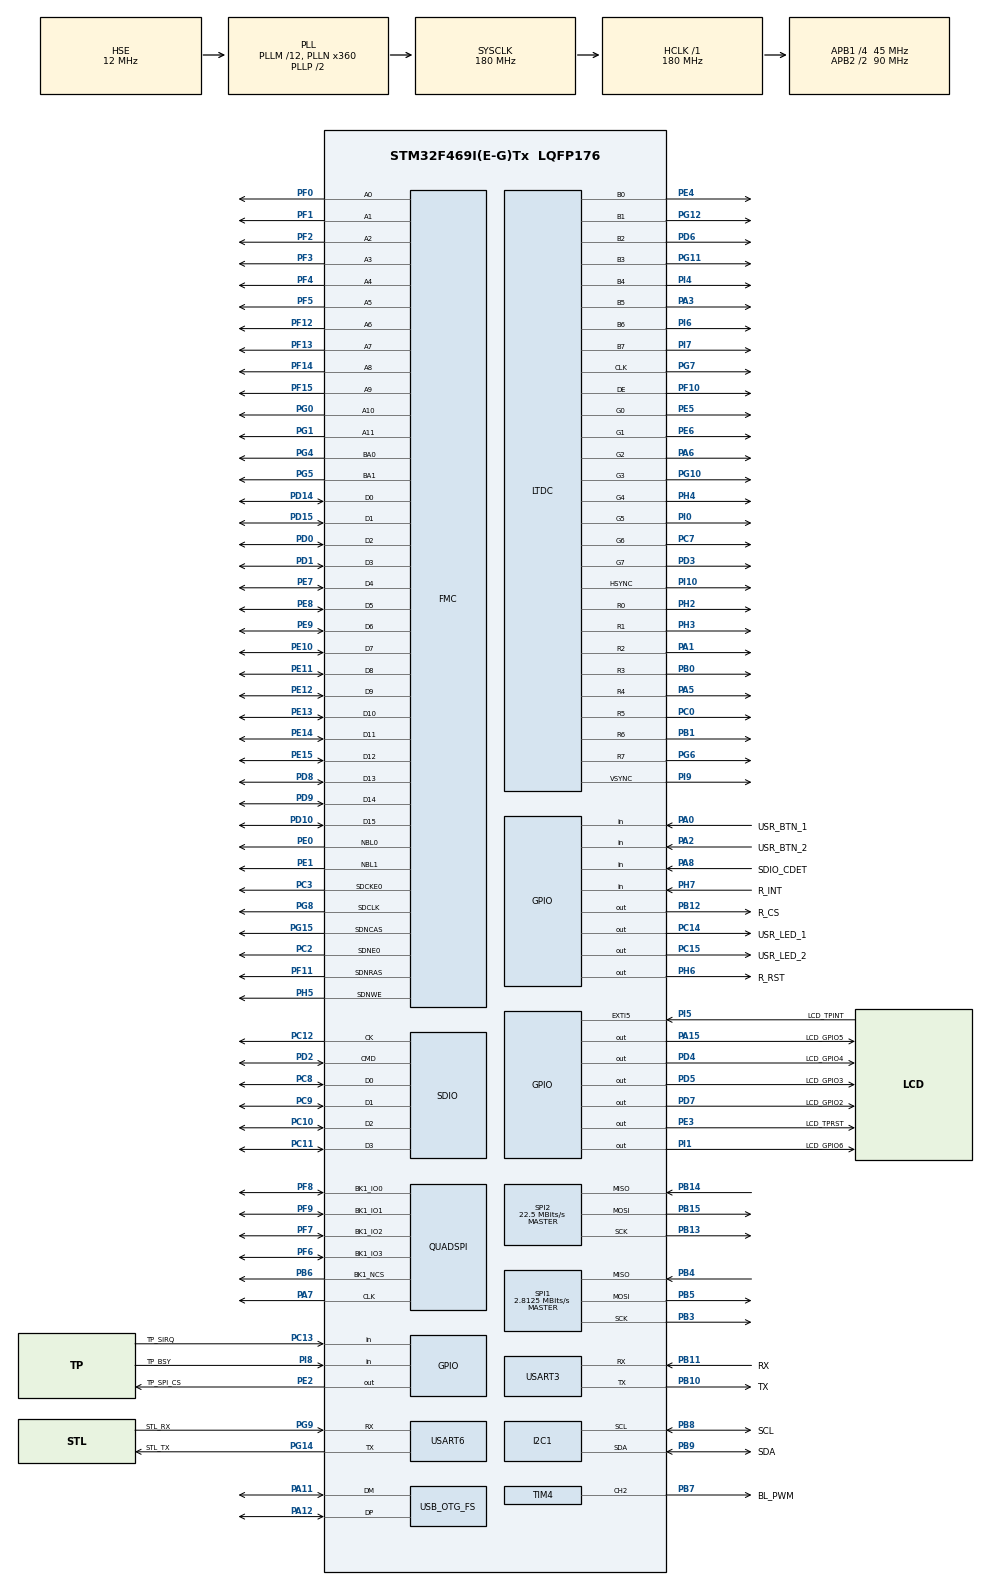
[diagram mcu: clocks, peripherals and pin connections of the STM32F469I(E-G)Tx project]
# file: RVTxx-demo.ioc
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SH.FMC_D7_DA7.0=FMC_D7,sd-16b-d1
VP_SYS_VS_tim6.Mode=TIM6
FMC.RCDDelay1=2
FMC.SDClockPeriod1=FMC_SDRAM_CLOCK_PERIOD_2
SH.FMC_A0.0=FMC_A0,12b-sda1
QUADSPI.ClockPrescaler=1
SPI1.VirtualType=VM_MASTER
FATFS0.BSP.api=Unknown
SPI2.VirtualType=VM_MASTER
PB10.Mode=Asynchronous
NVIC.TIM6_DAC_IRQn=true\:0\:0\:false\:false\:true\:false\:false\:true
VP_FATFS_VS_SDIO.Mode=SDIO
PG4.Signal=FMC_A14_BA0
PG8.Signal=FMC_SDCLK
PC12.Signal=SDIO_CK
PH6.GPIO_Label=R_RST
PG0.Signal=FMC_A10
FMC.LoadToActiveDelay1=2
SH.FMC_D5_DA5.0=FMC_D5,sd-16b-d1
PA3.GPIO_Speed=GPIO_SPEED_FREQ_VERY_HIGH
PB13.Signal=SPI2_SCK
PD3.GPIO_Speed=GPIO_SPEED_FREQ_VERY_HIGH
PG6.Mode=RGB888
RCC.SYSCLKSource=RCC_SYSCLKSOURCE_PLLCLK
SH.FMC_A15_BA1.0=FMC_BA1,FourSdramBanks1
SH.FMC_D9_DA9.0=FMC_D9,sd-16b-d1
FREERTOS.configENABLE_FPU=1
PH5.Signal=FMC_SDNWE
PF7.Signal=QUADSPI_BK1_IO2
SH.FMC_SDNWE.0=FMC_SDNWE,12b-sda1
SPI1.Direction=SPI_DIRECTION_2LINES
SH.FMC_D11_DA11.0=FMC_D11,sd-16b-d1
PD4.Signal=GPIO_Output
RCC.APB2TimFreq_Value=180000000
PB6.Signal=QUADSPI_BK1_NCS
PC7.Signal=LTDC_G6
PH1/OSC_OUT.Signal=RCC_OSC_OUT
PB6.Mode=Single Bank 1
SPI1.CalculateBaudRate=2.8125 MBits/s
PC3.Signal=FMC_SDCKE0
PD0.Signal=FMC_D2_DA2
PD8.Signal=FMC_D13_DA13
PE5.Signal=LTDC_G0
PE1.Signal=FMC_NBL1
QUADSPI.FlashSize=22
FREERTOS.configMINIMAL_STACK_SIZE=4096
FATFS0.BSP.ip=GPIO
PB3.Mode=Full_Duplex_Master
FATFS0.BSP.i2caddr=0
PB12.GPIO_Label=R_CS
PG14.Mode=Asynchronous
FMC.SelfRefreshTime1=4
LTDC.PixelFormat_L0=LTDC_PIXEL_FORMAT_RGB565
PB1.GPIO_Speed=GPIO_SPEED_FREQ_VERY_HIGH
PE9.Signal=FMC_D6_DA6
SH.FMC_A2.0=FMC_A2,12b-sda1
PB14.Mode=Full_Duplex_Master
PI6.Signal=LTDC_B6
STMicroelectronics.X-CUBE-TOUCHGFX.4.16.1.tgfx_display_interface=disp_ltdc
PC9.Mode=SD_4_bits_Wide_bus
SPI2.CalculateBaudRate=22.5 MBits/s
SH.S_TIM4_CH2.0=TIM4_CH2,PWM Generation2 CH2
PE2.Signal=GPIO_Output
PF8.Mode=Single Bank 1
PA8.Signal=GPIO_Input
SH.FMC_D1_DA1.0=FMC_D1,sd-16b-d1
TIM4.Period=1280
PF3.Signal=FMC_A3
VP_FREERTOS_VS_CMSIS_V1.Mode=CMSIS_V1
PD3.Mode=RGB888
PE10.Signal=FMC_D7_DA7
LTDC.HSync=15
Mcu.Package=LQFP176
PB9.Signal=I2C1_SDA
PI10.GPIO_Speed=GPIO_SPEED_FREQ_VERY_HIGH
PB1.Signal=LTDC_R6
NVIC.TimeBase=TIM6_DAC_IRQn
SPI2.Mode=SPI_MODE_MASTER
PH3.GPIO_Speed=GPIO_SPEED_FREQ_VERY_HIGH
FATFS0.BSP.solution=PA8
STMicroelectronics.X-CUBE-TOUCHGFX.4.16.1.ApplicationCcGraphicsJjApplication=TouchGFXOoGenerator
PI6.GPIO_Speed=GPIO_SPEED_FREQ_VERY_HIGH
NVIC.TimeBaseIP=TIM6
FMC.WriteRecoveryTime1=3
PC11.Mode=SD_4_bits_Wide_bus
SH.FMC_A1.0=FMC_A1,12b-sda1
PH2.Signal=LTDC_R0
RCC.APB2CLKDivider=RCC_HCLK_DIV2
SH.FMC_SDCLK.0=FMC_SDCLK,12b-sda1
PI7.Mode=RGB888
LTDC.VSync=15
PF14.Signal=FMC_A8
RCC.APB1TimFreq_Value=90000000
VP_DMA2D_VS_DMA2D.Mode=DMA2D_Activate
PC14/OSC32_IN.GPIO_Label=USR_LED_1
PF10.Mode=RGB888
FMC.RowCycleDelay1=7
PB13.Mode=Full_Duplex_Master
PA6.GPIO_Speed=GPIO_SPEED_FREQ_VERY_HIGH
PD15.Signal=FMC_D1_DA1
SH.FMC_D3_DA3.0=FMC_D3,sd-16b-d1
PG6.GPIO_Speed=GPIO_SPEED_FREQ_VERY_HIGH
PA5.Mode=RGB888
PG12.Signal=LTDC_B1
VP_STMicroelectronics.X-CUBE-TOUCHGFX_VS_GraphicsJjApplication_4.16.1.Mode=GraphicsJjApplication
FATFS0.BSP.STBoard=false
SH.FMC_A4.0=FMC_A4,12b-sda1
FREERTOS.Tasks01=defaultTask,0,4097,StartDefaultTask,Default,NULL,Dynamic,NULL,NULL
STMicroelectronics.X-CUBE-TOUCHGFX.4.16.1.tgfx_address1=0xC0000000
STMicroelectronics.X-CUBE-TOUCHGFX.4.16.1.tgfx_address2=0xC0400000
PI4.Mode=RGB888
PG5.Signal=FMC_A15_BA1
PG9.Signal=USART6_RX
SH.FMC_D10_DA10.0=FMC_D10,sd-16b-d1
PC13.Signal=GPIO_Input
FATFS0.BSP.mode=Input
PD3.Signal=LTDC_G7
PI10.Mode=RGB888
PG9.Mode=Asynchronous
PC2.Signal=FMC_SDNE0
PB11.GPIO_Label=RX
PD7.Signal=GPIO_Output
PD1.Signal=FMC_D3_DA3
PC0.Signal=LTDC_R5
RCC.APB1CLKDivider=RCC_HCLK_DIV4
PD6.Mode=RGB888
PG10.Signal=LTDC_G3
LTDC.ImageWidth_L0=1024
PD10.Signal=FMC_D15_DA15
PA3.Mode=RGB888
SH.FMC_A3.0=FMC_A3,12b-sda1
PB8.GPIO_Label=SCL
PI8.GPIO_Label=TP_BSY
PA8.GPIO_Label=SDIO_CDET
FMC.CASLatency1=FMC_SDRAM_CAS_LATENCY_3
PB11.Mode=Asynchronous
PI0.GPIO_Speed=GPIO_SPEED_FREQ_VERY_HIGH
SH.FMC_D15_DA15.0=FMC_D15,sd-16b-d1
I2C1.I2C_Mode=I2C_Fast
PA9.Signal=USB_OTG_FS_VBUS
PI6.Mode=RGB888
SDIO.ClockDiv=16
PB10.Signal=USART3_TX
PB14.Signal=SPI2_MISO
FATFS.BSP.number=1
RCC.USBCLockSelection=RCC_CLK48CLKSOURCE_PLLSAIP
PA5.Signal=LTDC_R4
PC12.Mode=SD_4_bits_Wide_bus
PI7.Signal=LTDC_B7
FMC.ReadBurst1=FMC_SDRAM_RBURST_ENABLE
SH.FMC_A6.0=FMC_A6,12b-sda1
FMC.ReadBurst2=FMC_SDRAM_RBURST_ENABLE
PA1.Mode=RGB888
PE14.Signal=FMC_D11_DA11
PE6.Mode=RGB888
PE15.Signal=FMC_D12_DA12
PE8.Signal=FMC_D5_DA5
PI7.GPIO_Speed=GPIO_SPEED_FREQ_VERY_HIGH
SPI1.Mode=SPI_MODE_MASTER
PH4.GPIO_Speed=GPIO_SPEED_FREQ_VERY_HIGH
PI1.Signal=GPIO_Output
PA0/WKUP.GPIO_Label=USR_BTN_1
PF13.Signal=FMC_A7
PA0/WKUP.GPIO_PuPd=GPIO_PULLUP
FATFS._USE_FIND=1
PA13.Mode=Serial_Wire
PG14.GPIO_Label=STL_TX
SH.FMC_SDNCAS.0=FMC_SDNCAS,12b-sda1
PH4.Mode=RGB888
PC8.Mode=SD_4_bits_Wide_bus
PB5.Signal=SPI1_MOSI
SH.FMC_A5.0=FMC_A5,12b-sda1
PG11.Mode=RGB888
LTDC.Alpha_L0=255
PA11.Signal=USB_OTG_FS_DM
ProjectManager.HeapSize=0x2000
PB1.Mode=RGB888
PH6.Signal=GPIO_Output
PF6.Mode=Single Bank 1
PF9.Signal=QUADSPI_BK1_IO1
NVIC.PriorityGroup=NVIC_PRIORITYGROUP_4
PB8.Mode=I2C
PE3.Signal=GPIO_Output
PC15/OSC32_OUT.Signal=GPIO_Output
PF4.Signal=FMC_A4
PD2.Signal=SDIO_CMD
PB0.Signal=LTDC_R3
FATFS0.BSP.name=Detect_SDIO
PI1.GPIO_Label=LCD_GPIO6
Mcu.Family=STM32F4
PC3.Mode=SdramChipSelect1_1
LTDC.BlendingFactor1_L0=LTDC_BLENDING_FACTOR1_CA
PA2.GPIO_PuPd=GPIO_PULLUP
SDIO.ClockEdge=SDIO_CLOCK_EDGE_RISING
PA6.Mode=RGB888
SH.FMC_A8.0=FMC_A8,12b-sda1
RCC.CortexFreq_Value=180000000
PC15/OSC32_OUT.GPIO_Label=USR_LED_2
PG6.Signal=LTDC_R7
SH.FMC_D14_DA14.0=FMC_D14,sd-16b-d1
LTDC.HBP=160
STMicroelectronics.X-CUBE-TOUCHGFX.4.16.1.tgfx_buffering_strategy=Double
PC10.Signal=SDIO_D2
SH.FMC_NBL0.0=FMC_NBL0,Sd2ByteEnable1
SH.FMC_D6_DA6.0=FMC_D6,sd-16b-d1
PA11.Mode=Device_Only
PA0/WKUP.Signal=GPIO_Input
SH.FMC_A14_BA0.0=FMC_BA0,FourSdramBanks1
SH.FMC_A11.0=FMC_A11,12b-sda1
PI5.GPIO_Label=LCD_TPINT
PI9.GPIO_Speed=GPIO_SPEED_FREQ_VERY_HIGH
PC13.GPIO_Label=TP_SIRQ
PB11.Signal=USART3_RX
PB15.Signal=SPI2_MOSI
STMicroelectronics.X-CUBE-TOUCHGFX.4.16.1.tgfx_location=By Address
PG11.Signal=LTDC_B3
PG15.Signal=FMC_SDNCAS
ProjectManager.StackSize=0x5000
PH3.Mode=RGB888
PA15.GPIO_Label=LCD_GPIO5
SH.FMC_A7.0=FMC_A7,12b-sda1
PA12.Signal=USB_OTG_FS_DP
PH0/OSC_IN.Mode=HSE-External-Oscillator
RCC.HCLKFreq_Value=180000000
SH.FMC_NBL1.0=FMC_NBL1,Sd2ByteEnable1
LTDC.WindowX1_L0=1024
PF12.Signal=FMC_A6
PI9.Mode=RGB888
SH.FMC_A10.0=FMC_A10,12b-sda1
RCC.AHBFreq_Value=180000000
SPI2.BaudRatePrescaler=SPI_BAUDRATEPRESCALER_2
RCC.HSE_VALUE=12000000
SH.FMC_D8_DA8.0=FMC_D8,sd-16b-d1
FMC.ExitSelfRefreshDelay1=7
FMC.RPDelay1=2
PI8.Signal=GPIO_Input
SH.FMC_D2_DA2.0=FMC_D2,sd-16b-d1
PG11.GPIO_Speed=GPIO_SPEED_FREQ_VERY_HIGH
LTDC.VBP=23
PF9.Mode=Single Bank 1
PB4.Mode=Full_Duplex_Master
PE13.Signal=FMC_D10_DA10
PH7.GPIO_Label=R_INT
PA14.Mode=Serial_Wire
PI5.Signal=GPXTI5
PI4.GPIO_Speed=GPIO_SPEED_FREQ_VERY_HIGH
PI0.Signal=LTDC_G5
PF11.Signal=FMC_SDNRAS
PB5.Mode=Full_Duplex_Master
PC13.GPIO_PuPd=GPIO_NOPULL
LTDC.HFP=160
PB7.Signal=S_TIM4_CH2
LTDC.BlendingFactor2_L0=LTDC_BLENDING_FACTOR2_CA
FMC.ReadPipeDelay1=FMC_SDRAM_RPIPE_DELAY_1
FMC.ReadPipeDelay2=FMC_SDRAM_RPIPE_DELAY_1
PE4.Mode=RGB888
SH.FMC_SDNRAS.0=FMC_SDNRAS,12b-sda1
DMA2D.ColorMode=DMA2D_OUTPUT_RGB888
LTDC.ActiveW=1024
PH1/OSC_OUT.Mode=HSE-External-Oscillator
PE4.Signal=LTDC_B0
FREERTOS.configTOTAL_HEAP_SIZE=55360
PD7.GPIO_Label=LCD_GPIO2
PB7.GPIO_Label=BL_PWM
PA6.Signal=LTDC_G2
SH.FMC_D0_DA0.0=FMC_D0,sd-16b-d1
USART6.VirtualMode=VM_ASYNC
PC14/OSC32_IN.Signal=GPIO_Output
PD5.GPIO_Label=LCD_GPIO3
PA2.GPIO_Label=USR_BTN_2
USB_OTG_FS.VirtualMode=Device_Only
SH.FMC_A9.0=FMC_A9,12b-sda1
PA15.Signal=GPIO_Output
PF8.Signal=QUADSPI_BK1_IO0
SH.FMC_D4_DA4.0=FMC_D4,sd-16b-d1
RCC.PLLSAIN=384
PF5.Signal=FMC_A5
RCC.PLLSAIP=RCC_PLLSAIP_DIV8
RCC.PLLSAIR=4
PH7.Signal=GPIO_Input
SPI2.Direction=SPI_DIRECTION_2LINES
PF0.Signal=FMC_A0
PH2.Mode=RGB888
PE7.Signal=FMC_D4_DA4
PD6.Signal=LTDC_B2
SPI1.BaudRatePrescaler=SPI_BAUDRATEPRESCALER_32
PE2.GPIO_Label=TP_SPI_CS
STMicroelectronics.X-CUBE-TOUCHGFX.4.16.1.tgfx_vsync=vsync_ltdc
PB4.Signal=SPI1_MISO
PA3.Signal=LTDC_B5
RCC.PLLSourceVirtual=RCC_PLLSOURCE_HSE
QUADSPI.ChipSelectHighTime=QSPI_CS_HIGH_TIME_4_CYCLE
NVIC.LTDC_IRQn=true\:5\:0\:true\:false\:true\:false\:true\:true
LTDC.FBStartAdress_L0=0xC0000000
LTDC.VFP=12
LTDC.WindowY1_L0=600
PA7.Mode=Single Bank 1
PG7.Signal=LTDC_CLK
PB9.GPIO_Label=SDA
PG1.Signal=FMC_A11
PC11.Signal=SDIO_D3
PC8.Signal=SDIO_D0
PF10.GPIO_Speed=GPIO_SPEED_FREQ_VERY_HIGH
PC10.Mode=SD_4_bits_Wide_bus
PG10.Mode=RGB888
PC2.Mode=SdramChipSelect1_1
PI10.Signal=LTDC_HSYNC
PD9.Signal=FMC_D14_DA14
PD5.Signal=GPIO_Output
PG10.GPIO_Speed=GPIO_SPEED_FREQ_VERY_HIGH
PC0.Mode=RGB888
USB_OTG_FS.low_power_enable=DISABLE
PB0.GPIO_Speed=GPIO_SPEED_FREQ_VERY_HIGH
FATFS0.BSP.instance=PA8
PA13.Signal=SYS_JTMS-SWDIO
PF7.Mode=Single Bank 1
PC0.GPIO_Speed=GPIO_SPEED_FREQ_VERY_HIGH
PH4.Signal=LTDC_G4
PF6.Signal=QUADSPI_BK1_IO3
STMicroelectronics.X-CUBE-TOUCHGFX.4.16.1.tgfx_hardware_accelerator=dma_2d
ProjectManager.TargetToolchain=STM32CubeIDE
PB10.GPIO_Label=TX
SH.FMC_D13_DA13.0=FMC_D13,sd-16b-d1
LTDC.ActiveH=600
PI0.Mode=RGB888
PB9.Mode=I2C
PF2.Signal=FMC_A2
RCC.USBFreq_Value=48000000
TIM4.Prescaler=50
PE11.Signal=FMC_D8_DA8
PG7.Mode=RGB888
RCC.LSE_VALUE=32768
PA1.Signal=LTDC_R2
PD2.Mode=SD_4_bits_Wide_bus
PG9.GPIO_Label=STL_RX
PG14.Signal=USART6_TX
PB0.Mode=RGB888
board=custom
PG12.Mode=RGB888
PC7.GPIO_Speed=GPIO_SPEED_FREQ_VERY_HIGH
RCC.VCOOutputFreq_Value=360000000
PI9.Signal=LTDC_VSYNC
PB15.Mode=Full_Duplex_Master
PH0/OSC_IN.Signal=RCC_OSC_IN
TIM4.Channel-PWM\ Generation2\ CH2=TIM_CHANNEL_2
PG7.GPIO_Speed=GPIO_SPEED_FREQ_VERY_HIGH
RCC.APB2Freq_Value=90000000
LTDC.Layers=0
PD4.GPIO_Label=LCD_GPIO4
PF10.Signal=LTDC_DE
PI4.Signal=LTDC_B4
PE5.Mode=RGB888
SH.FMC_D12_DA12.0=FMC_D12,sd-16b-d1
PF15.Signal=FMC_A9
USB_OTG_FS.Sof_enable=DISABLE
PF1.Signal=FMC_A1
PE6.Signal=LTDC_G1
Mcu.Name=STM32F469I(E-G)Tx
PE0.Signal=FMC_NBL0
PE12.Signal=FMC_D9_DA9
PA2.Signal=GPIO_Input
PD14.Signal=FMC_D0_DA0
PB3.Signal=SPI1_SCK
RCC.SYSCLKFreq_VALUE=180000000
PA12.Mode=Device_Only
USART3.VirtualMode=VM_ASYNC
PA14.Signal=SYS_JTCK-SWCLK
RCC.HSI_VALUE=16000000
PA8.GPIO_PuPd=GPIO_PULLUP
PA5.GPIO_Speed=GPIO_SPEED_FREQ_VERY_HIGH
RCC.PLLQ=7
PH3.Signal=LTDC_R1
RCC.PLLM=12
RCC.PLLN=360
PB8.Signal=I2C1_SCL
PE3.GPIO_Label=LCD_TPRST
PC9.Signal=SDIO_D1
PC7.Mode=RGB888
RCC.APB1Freq_Value=45000000
VP_CRC_VS_CRC.Mode=CRC_Activate
LTDC.ImageHeight_L0=600
DMA2D.Mode=DMA2D_M2M
PB12.Signal=GPIO_Output
PA7.Signal=QUADSPI_CLK

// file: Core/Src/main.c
/* USER CODE BEGIN Header */
/**
  ******************************************************************************
  * @file           : main.c
  * @brief          : Main program body
  ******************************************************************************
  * @attention
  *
  * <h2><center>&copy; Copyright (c) 2020 STMicroelectronics.
  * All rights reserved.</center></h2>
  *
  * This software component is licensed by ST under Ultimate Liberty license
  * SLA0044, the "License"; You may not use this file except in compliance with
  * the License. You may obtain a copy of the License at:
  *                             www.st.com/SLA0044
  *
  ******************************************************************************
  */
/* USER CODE END Header */
#include "main.h"
#include "cmsis_os.h"
#include "crc.h"
#include "dma2d.h"
#include "fatfs.h"
#include "i2c.h"
#include "ltdc.h"
#include "quadspi.h"
#include "sdio.h"
#include "spi.h"
#include "tim.h"
#include "usart.h"
#include "usb_otg.h"
#include "gpio.h"
#include "fmc.h"
#include "app_touchgfx.h"

/* USER CODE BEGIN Includes */

#include "bsp_adc_touch.h"
#include "bsp_button.h"
#include "bsp_display.h"
#include "bsp_flash.h"
#include "bsp_led.h"
#include "bsp_print.h"
#include "bsp_ribus.h"
#include "bsp_sdcard.h"
#include "bsp_sdram.h"
#include "bsp_touch.h"
#include "bsp_sdcard.h"
#include "demo.h"

/* USER CODE END Includes */

void SystemClock_Config(void);
void MX_FREERTOS_Init(void);

int main(void)
{

  /* MCU Configuration--------------------------------------------------------*/

  /* Reset of all peripherals, Initializes the Flash interface and the Systick. */
  HAL_Init();

  /* Configure the system clock */
  SystemClock_Config();

  /* Initialize all configured peripherals */
  MX_GPIO_Init();
  MX_FMC_Init();
  MX_I2C1_Init();
  MX_LTDC_Init();
  MX_QUADSPI_Init();
  MX_SDIO_SD_Init();
  MX_SPI1_Init();
  MX_SPI2_Init();
  MX_USART3_UART_Init();
  MX_USART6_UART_Init();
  MX_FATFS_Init();
  MX_USB_OTG_FS_PCD_Init();
  MX_CRC_Init();
  MX_DMA2D_Init();
  MX_TIM4_Init();
  MX_TouchGFX_Init();
  /* USER CODE BEGIN 2 */

  // -------------------------------------- Initialization
  BSP_QSPI_EnableMemoryMappedMode();
  BSP_SDRAM_Initliazation( );
  BSP_Print( "\r\n\r\n------------------" );
  BSP_Print( "\r\nGetting display and TP info\r\n" );

  if ( DEMO_DisplaySizeSelection( ) )
  {
    BSP_Print( "\r\n\tLoad configuration from flash" );
    DEMO_RestoreConfiguratiion( );

  }
  else
  {
	DEMO_DisplayTypeSelection( );

    if ( DEMO_RibusDisplayQuery( ) )
	{
	  BSP_Print( "\r\n\tRiBUS Display found" );
	}

    DEMO_StoreConfiguratiion( );
  }

  BSP_Print( "\r\n\r\n------------------" );
  BSP_Print( "\r\nInitlization display and TP\r\n" );
  //DEMO_Initialize();

/* Configure QSPI: LPTR register with the low-power time out value */
	WRITE_REG(QUADSPI->LPTR, 0xFFF);

  BSP_Display_Enable( );
  HAL_TIM_PWM_Start(&htim4, TIM_CHANNEL_2);

 // BSP_CapTouch_Initialize( CAP_TOUCH_RGB_7_0 );
  /* USER CODE END 2 */

  /* Call init function for freertos objects (in freertos.c) */
  MX_FREERTOS_Init();
  /* Start scheduler */
  osKernelStart();

  /* We should never get here as control is now taken by the scheduler */
  /* Infinite loop */
  while (1)
  {

    /* USER CODE BEGIN 3 */

//	DEMO_Run( );
  }

  /* USER CODE END 3 */
}

void SystemClock_Config(void)
{
  RCC_OscInitTypeDef RCC_OscInitStruct = {0};
  RCC_ClkInitTypeDef RCC_ClkInitStruct = {0};
  RCC_PeriphCLKInitTypeDef PeriphClkInitStruct = {0};

  /** Configure the main internal regulator output voltage
  */
  __HAL_RCC_PWR_CLK_ENABLE();
  __HAL_PWR_VOLTAGESCALING_CONFIG(PWR_REGULATOR_VOLTAGE_SCALE1);
  /** Initializes the RCC Oscillators according to the specified parameters
  * in the RCC_OscInitTypeDef structure.
  */
  RCC_OscInitStruct.OscillatorType = RCC_OSCILLATORTYPE_HSE;
  RCC_OscInitStruct.HSEState = RCC_HSE_ON;
  RCC_OscInitStruct.PLL.PLLState = RCC_PLL_ON;
  RCC_OscInitStruct.PLL.PLLSource = RCC_PLLSOURCE_HSE;
  RCC_OscInitStruct.PLL.PLLM = 12;
  RCC_OscInitStruct.PLL.PLLN = 360;
  RCC_OscInitStruct.PLL.PLLP = RCC_PLLP_DIV2;
  RCC_OscInitStruct.PLL.PLLQ = 7;
  RCC_OscInitStruct.PLL.PLLR = 2;
  if (HAL_RCC_OscConfig(&RCC_OscInitStruct) != HAL_OK)
  {
    Error_Handler();
  }
  /** Activate the Over-Drive mode
  */
  if (HAL_PWREx_EnableOverDrive() != HAL_OK)
  {
    Error_Handler();
  }
  /** Initializes the CPU, AHB and APB buses clocks
  */
  RCC_ClkInitStruct.ClockType = RCC_CLOCKTYPE_HCLK|RCC_CLOCKTYPE_SYSCLK
                              |RCC_CLOCKTYPE_PCLK1|RCC_CLOCKTYPE_PCLK2;
  RCC_ClkInitStruct.SYSCLKSource = RCC_SYSCLKSOURCE_PLLCLK;
  RCC_ClkInitStruct.AHBCLKDivider = RCC_SYSCLK_DIV1;
  RCC_ClkInitStruct.APB1CLKDivider = RCC_HCLK_DIV4;
  RCC_ClkInitStruct.APB2CLKDivider = RCC_HCLK_DIV2;

  if (HAL_RCC_ClockConfig(&RCC_ClkInitStruct, FLASH_LATENCY_5) != HAL_OK)
  {
    Error_Handler();
  }
  PeriphClkInitStruct.PeriphClockSelection = RCC_PERIPHCLK_SDIO|RCC_PERIPHCLK_CLK48
                              |RCC_PERIPHCLK_LTDC;
  PeriphClkInitStruct.PLLSAI.PLLSAIN = 384;
  PeriphClkInitStruct.PLLSAI.PLLSAIR = 4;
  PeriphClkInitStruct.PLLSAI.PLLSAIP = RCC_PLLSAIP_DIV8;
  PeriphClkInitStruct.PLLSAIDivR = RCC_PLLSAIDIVR_2;
  PeriphClkInitStruct.Clk48ClockSelection = RCC_CLK48CLKSOURCE_PLLSAIP;
  PeriphClkInitStruct.SdioClockSelection = RCC_SDIOCLKSOURCE_CLK48;
  if (HAL_RCCEx_PeriphCLKConfig(&PeriphClkInitStruct) != HAL_OK)
  {
    Error_Handler();
  }
}

 /**
  * @brief  Period elapsed callback in non blocking mode
  * @note   This function is called  when TIM6 interrupt took place, inside
  * HAL_TIM_IRQHandler(). It makes a direct call to HAL_IncTick() to increment
  * a global variable "uwTick" used as application time base.
  * @param  htim : TIM handle
  * @retval None
  */
void HAL_TIM_PeriodElapsedCallback(TIM_HandleTypeDef *htim)
{
  if (htim->Instance == TIM6) {
    HAL_IncTick();
  }
}

void Error_Handler(void)
{
}

/************************ (C) COPYRIGHT STMicroelectronics *****END OF FILE****/

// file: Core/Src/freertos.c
/* USER CODE BEGIN Header */
/**
  ******************************************************************************
  * File Name          : freertos.c
  * Description        : Code for freertos applications
  ******************************************************************************
  * @attention
  *
  * <h2><center>&copy; Copyright (c) 2021 STMicroelectronics.
  * All rights reserved.</center></h2>
  *
  * This software component is licensed by ST under Ultimate Liberty license
  * SLA0044, the "License"; You may not use this file except in compliance with
  * the License. You may obtain a copy of the License at:
  *                             www.st.com/SLA0044
  *
  ******************************************************************************
  */
/* USER CODE END Header */

#include "FreeRTOS.h"
#include "task.h"
#include "main.h"
#include "cmsis_os.h"

/* USER CODE BEGIN Includes */
#include "app_touchgfx.h"
/* USER CODE END Includes */

osThreadId defaultTaskHandle;

void StartDefaultTask(void const * argument);

void MX_FREERTOS_Init(void); /* (MISRA C 2004 rule 8.1) */

/* GetIdleTaskMemory prototype (linked to static allocation support) */
void vApplicationGetIdleTaskMemory( StaticTask_t **ppxIdleTaskTCBBuffer, StackType_t **ppxIdleTaskStackBuffer, uint32_t *pulIdleTaskStackSize );

/* USER CODE BEGIN GET_IDLE_TASK_MEMORY */
static StaticTask_t xIdleTaskTCBBuffer;
static StackType_t xIdleStack[configMINIMAL_STACK_SIZE];

void vApplicationGetIdleTaskMemory( StaticTask_t **ppxIdleTaskTCBBuffer, StackType_t **ppxIdleTaskStackBuffer, uint32_t *pulIdleTaskStackSize )
{
  *ppxIdleTaskTCBBuffer = &xIdleTaskTCBBuffer;
  *ppxIdleTaskStackBuffer = &xIdleStack[0];
  *pulIdleTaskStackSize = configMINIMAL_STACK_SIZE;
  /* place for user code */
}
/* USER CODE END GET_IDLE_TASK_MEMORY */

void MX_FREERTOS_Init(void) {

  /* Create the thread(s) */
  /* definition and creation of defaultTask */
  osThreadDef(defaultTask, StartDefaultTask, osPriorityNormal, 0, 4097);
  defaultTaskHandle = osThreadCreate(osThread(defaultTask), NULL);

}

void StartDefaultTask(void const * argument)
{
  /* USER CODE BEGIN StartDefaultTask */
	  MX_TouchGFX_Process();

  /* Infinite loop */
  for(;;)
  {
    osDelay(1);
  }
  /* USER CODE END StartDefaultTask */
}

/************************ (C) COPYRIGHT STMicroelectronics *****END OF FILE****/
